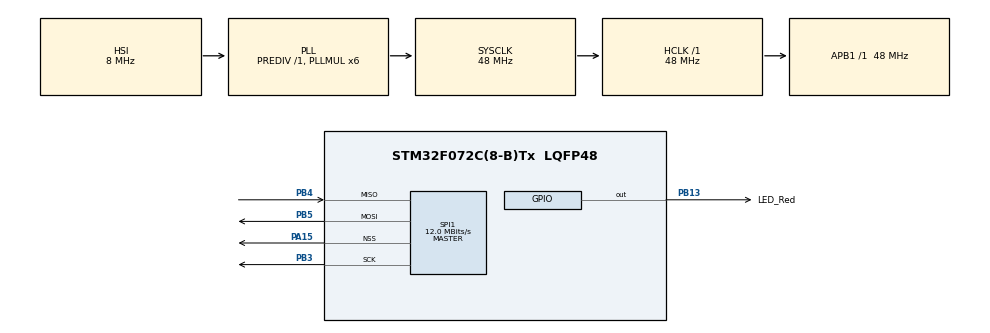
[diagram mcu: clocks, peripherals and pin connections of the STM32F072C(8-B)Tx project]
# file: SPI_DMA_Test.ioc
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Dma.Request0=SPI1_TX
Dma.Request1=SPI1_RX
Dma.SPI1_RX.1.Direction=DMA_PERIPH_TO_MEMORY
Dma.SPI1_RX.1.Instance=DMA1_Channel2
Dma.SPI1_RX.1.MemDataAlignment=DMA_MDATAALIGN_BYTE
Dma.SPI1_RX.1.MemInc=DMA_MINC_ENABLE
Dma.SPI1_RX.1.Mode=DMA_NORMAL
Dma.SPI1_RX.1.PeriphDataAlignment=DMA_PDATAALIGN_BYTE
Dma.SPI1_RX.1.PeriphInc=DMA_PINC_DISABLE
Dma.SPI1_RX.1.Priority=DMA_PRIORITY_MEDIUM
Dma.SPI1_TX.0.Direction=DMA_MEMORY_TO_PERIPH
Dma.SPI1_TX.0.Instance=DMA1_Channel3
Dma.SPI1_TX.0.MemDataAlignment=DMA_MDATAALIGN_BYTE
Dma.SPI1_TX.0.MemInc=DMA_MINC_ENABLE
Dma.SPI1_TX.0.Mode=DMA_NORMAL
Dma.SPI1_TX.0.PeriphDataAlignment=DMA_PDATAALIGN_BYTE
Dma.SPI1_TX.0.PeriphInc=DMA_PINC_DISABLE
Dma.SPI1_TX.0.Priority=DMA_PRIORITY_MEDIUM
Mcu.Family=STM32F0
Mcu.Name=STM32F072C(8-B)Tx
Mcu.Package=LQFP48
NVIC.DMA1_Channel2_3_IRQn=true\:0\:0\:false\:false\:true\:false\:true
NVIC.SPI1_IRQn=true\:0\:0\:false\:false\:true\:true\:true
PA13.Mode=Serial_Wire
PA13.Signal=SYS_SWDIO
PA14.Mode=Serial_Wire
PA14.Signal=SYS_SWCLK
PA15.Mode=NSS_Signal_Hard_Output
PA15.Signal=SPI1_NSS
PB13.GPIO_Label=LED_Red
PB13.Signal=GPIO_Output
PB3.Mode=Full_Duplex_Master
PB3.Signal=SPI1_SCK
PB4.Mode=Full_Duplex_Master
PB4.Signal=SPI1_MISO
PB5.Mode=Full_Duplex_Master
PB5.Signal=SPI1_MOSI
PF0-OSC_IN.Mode=HSE-External-Oscillator
PF0-OSC_IN.Signal=RCC_OSC_IN
PF1-OSC_OUT.Mode=HSE-External-Oscillator
PF1-OSC_OUT.Signal=RCC_OSC_OUT
ProjectManager.HeapSize=0x200
ProjectManager.StackSize=0x400
ProjectManager.TargetToolchain=MDK-ARM V5
RCC.AHBFreq_Value=48000000
RCC.APB1Freq_Value=48000000
RCC.APB1TimFreq_Value=48000000
RCC.HCLKFreq_Value=48000000
RCC.PLLMUL=RCC_PLL_MUL6
RCC.SYSCLKFreq_VALUE=48000000
RCC.SYSCLKSource=RCC_SYSCLKSOURCE_PLLCLK
SPI1.BaudRatePrescaler=SPI_BAUDRATEPRESCALER_4
SPI1.CalculateBaudRate=12.0 MBits/s
SPI1.DataSize=SPI_DATASIZE_8BIT
SPI1.Direction=SPI_DIRECTION_2LINES
SPI1.Mode=SPI_MODE_MASTER
SPI1.VirtualNSS=VM_NSSHARD
SPI1.VirtualType=VM_MASTER
board=custom

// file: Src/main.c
/* USER CODE BEGIN Header */
/**
  ******************************************************************************
  * @file           : main.c
  * @brief          : Main program body
  ******************************************************************************
  * @attention
  *
  * <h2><center>&copy; Copyright (c) 2021 STMicroelectronics.
  * All rights reserved.</center></h2>
  *
  * This software component is licensed by ST under BSD 3-Clause license,
  * the "License"; You may not use this file except in compliance with the
  * License. You may obtain a copy of the License at:
  *                        opensource.org/licenses/BSD-3-Clause
  *
  ******************************************************************************
  */
/* USER CODE END Header */

#include "main.h"
#include "dma.h"
#include "spi.h"
#include "gpio.h"
#include "sx1280_hal.h"
#include "sx1280_radio.h"

void SystemClock_Config(void);

  typedef enum
{
    APP_LOWPOWER,
    APP_RX,
    APP_RX_TIMEOUT,
    APP_RX_ERROR,
    APP_TX,
    APP_TX_TIMEOUT,
}AppStates_t;

AppStates_t AppState = APP_LOWPOWER;            //芯片初始状态
void OnTxDone( void )
{
    AppState = APP_TX;
}
void OnRxDone( void )
{
    AppState = APP_RX;
}
void OnTxTimeout( void )
{
    AppState = APP_TX_TIMEOUT;
}
void OnRxTimeout( void )
{
    AppState = APP_RX_TIMEOUT;
}
void OnRxError( IrqErrorCode_t errorCode )
{
    AppState = APP_RX_ERROR;
}
void OnRangingDone( IrqRangingCode_t val )
{

}
void OnCadDone( bool channelActivityDetected )
{

}

RadioCallbacks_t Callbacks =        //回调函数结构
{
    &OnTxDone,        // txDone
    &OnRxDone,        // rxDone
    NULL,             // syncWordDone 适用于FLRC模式
    NULL,             // headerDone   LoRa /测距引擎
    &OnTxTimeout,     // txTimeout
    &OnRxTimeout,     // rxTimeout
    &OnRxError,       // rxError
    NULL,             // rangingDone  测距引擎
    NULL,             // cadDone      LoRa /测距引擎
};

uint16_t RxIrqMask = IRQ_RX_DONE | IRQ_TX_DONE ;   //RX模式下会触发的中断
uint16_t TxIrqMask = IRQ_TX_DONE | IRQ_RX_DONE ;   //TX模式下会触发的中断

ModulationParams_t modulationParams;    //描述每种数据包类型的调制参数的类型
PacketParams_t packetParams;            //描述每种数据包类型的数据包参数的类型
PacketStatus_t packetStatus;            //代表每种数据包类型的数据包状态
uint32_t SX1280_ID;
int main(void)
{

  /* MCU Configuration--------------------------------------------------------*/

  /* Reset of all peripherals, Initializes the Flash interface and the Systick. */
  HAL_Init();

  /* Configure the system clock */
  SystemClock_Config();

  /* Initialize all configured peripherals */
  MX_GPIO_Init();
  MX_DMA_Init();
  MX_SPI1_Init();
  Radio.Init( &Callbacks );//初始化回调函数
  Radio.SetRegulatorMode( USE_DCDC ); // 也可以设置为LDO模式但消耗更多功率 USE_DCDC  USE_LDO

uint8_t txbuff[5]={0x19,0x01,0x53,0x00,0x00};
uint8_t rxbuff[5];
  /* Infinite loop */
  /* USER CODE BEGIN WHILE */
  while (1)
  {
    HAL_SPI_MY_TransmitReceive_DMA(&hspi1, txbuff,rxbuff,5);
    HAL_SPI_MY_TransmitReceive_DMA(&hspi1, txbuff,rxbuff,5);

    SX1280_ID = Radio.GetFirmwareVersion();//获取芯片信息 0xA9B7 可用于测试SPI的读写情况

    HAL_GPIO_TogglePin(LED_Red_GPIO_Port,LED_Red_Pin);
      HAL_Delay(50);
    /* USER CODE END WHILE */

  }
}

void SystemClock_Config(void)
{
  RCC_OscInitTypeDef RCC_OscInitStruct = {0};
  RCC_ClkInitTypeDef RCC_ClkInitStruct = {0};

  /** Initializes the CPU, AHB and APB busses clocks
  */
  RCC_OscInitStruct.OscillatorType = RCC_OSCILLATORTYPE_HSI;
  RCC_OscInitStruct.HSIState = RCC_HSI_ON;
  RCC_OscInitStruct.HSICalibrationValue = RCC_HSICALIBRATION_DEFAULT;
  RCC_OscInitStruct.PLL.PLLState = RCC_PLL_ON;
  RCC_OscInitStruct.PLL.PLLSource = RCC_PLLSOURCE_HSI;
  RCC_OscInitStruct.PLL.PLLMUL = RCC_PLL_MUL6;
  RCC_OscInitStruct.PLL.PREDIV = RCC_PREDIV_DIV1;
  if (HAL_RCC_OscConfig(&RCC_OscInitStruct) != HAL_OK)
  {
    Error_Handler();
  }
  /** Initializes the CPU, AHB and APB busses clocks
  */
  RCC_ClkInitStruct.ClockType = RCC_CLOCKTYPE_HCLK|RCC_CLOCKTYPE_SYSCLK
                              |RCC_CLOCKTYPE_PCLK1;
  RCC_ClkInitStruct.SYSCLKSource = RCC_SYSCLKSOURCE_PLLCLK;
  RCC_ClkInitStruct.AHBCLKDivider = RCC_SYSCLK_DIV1;
  RCC_ClkInitStruct.APB1CLKDivider = RCC_HCLK_DIV1;

  if (HAL_RCC_ClockConfig(&RCC_ClkInitStruct, FLASH_LATENCY_1) != HAL_OK)
  {
    Error_Handler();
  }
}

void Error_Handler(void)
{
}

/************************ (C) COPYRIGHT STMicroelectronics *****END OF FILE****/
